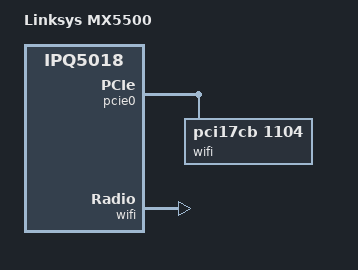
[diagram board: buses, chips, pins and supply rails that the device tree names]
// SPDX-License-Identifier: GPL-2.0-or-later OR MIT

/dts-v1/;

#include "ipq5018-mx-base.dtsi"

/ {
	model = "Linksys MX5500";
	compatible = "linksys,mx5500", "qcom,ipq5018";

	chosen {
		bootargs-append = " root=/dev/ubiblock0_0 coherent_pool=2M";
		stdout-path = "serial0:115200n8";
	};
};

&pcie0 {
	status = "okay";
	perst-gpios = <&tlmm 15 GPIO_ACTIVE_LOW>;

	pcie@0 {
		wifi@0,0 {
			status = "okay";
			compatible = "pci17cb,1104";
			qcom,ath11k-fw-memory-mode = <1>;
			qcom,ath11k-calibration-variant = "Linksys-MX5500";
			reg = <0x00010000 0 0 0 0>;
		};
	};
};

&wifi {
	status = "okay";

	qcom,rproc = <&q6v5_wcss>;
	qcom,ath11k-calibration-variant = "Linksys-MX5500";
};
